CM_ "IMPORT _honda_common.dbc";
CM_ "IMPORT _bosch_2018.dbc";
CM_ "IMPORT _lkas_hud_8byte.dbc";
CM_ "IMPORT _bosch_standstill.dbc";
CM_ "IMPORT _steering_sensors_a.dbc";
CM_ "IMPORT _gearbox_common.dbc";

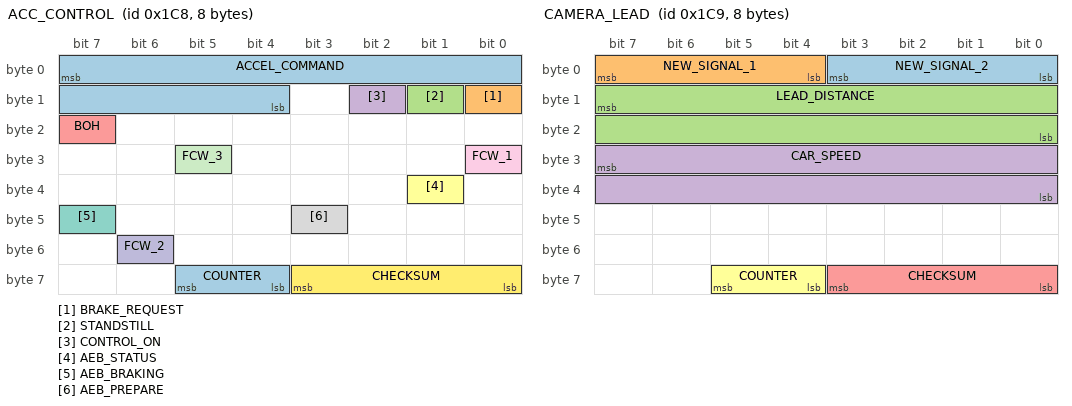
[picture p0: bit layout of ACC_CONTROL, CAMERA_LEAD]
BO_ 456 ACC_CONTROL: 8 XXX
 SG_ ACCEL_COMMAND : 7|12@0- (0.01,0) [0|0] "m/s^2" XXX
 SG_ BRAKE_REQUEST : 8|1@0+ (1,0) [0|1] "" XXX
 SG_ STANDSTILL : 9|1@0+ (1,0) [0|1] "" XXX
 SG_ CONTROL_ON : 10|1@0+ (1,0) [0|1] "" XXX
 SG_ BOH : 23|1@0+ (1,0) [0|1] "" XXX
 SG_ AEB_STATUS : 33|1@1+ (1,0) [0|7] "" XXX
 SG_ AEB_BRAKING : 47|1@0+ (1,0) [0|1] "" XXX
 SG_ AEB_PREPARE : 43|1@0+ (1,0) [0|1] "" XXX
 SG_ FCW_1 : 24|1@1+ (1,0) [0|3] "" XXX
 SG_ FCW_2 : 54|1@0+ (1,0) [0|3] "" XXX
 SG_ FCW_3 : 29|1@0+ (1,0) [0|1] "" XXX
 SG_ CHECKSUM : 59|4@0+ (1,0) [0|15] "" XXX
 SG_ COUNTER : 61|2@0+ (1,0) [0|3] "" XXX

BO_ 457 CAMERA_LEAD: 8 CAM
 SG_ NEW_SIGNAL_2 : 0|4@1+ (1,0) [0|15] "" XXX
 SG_ NEW_SIGNAL_1 : 4|4@1+ (1,0) [0|15] "" XXX
 SG_ LEAD_DISTANCE : 15|16@0+ (1,0) [0|65535] "cm" XXX
 SG_ CAR_SPEED : 31|16@0+ (0.03124,0) [0|65535] "kph" XXX
 SG_ CHECKSUM : 59|4@0+ (1,0) [0|15] "" XXX
 SG_ COUNTER : 61|2@0+ (1,0) [0|3] "" XXX

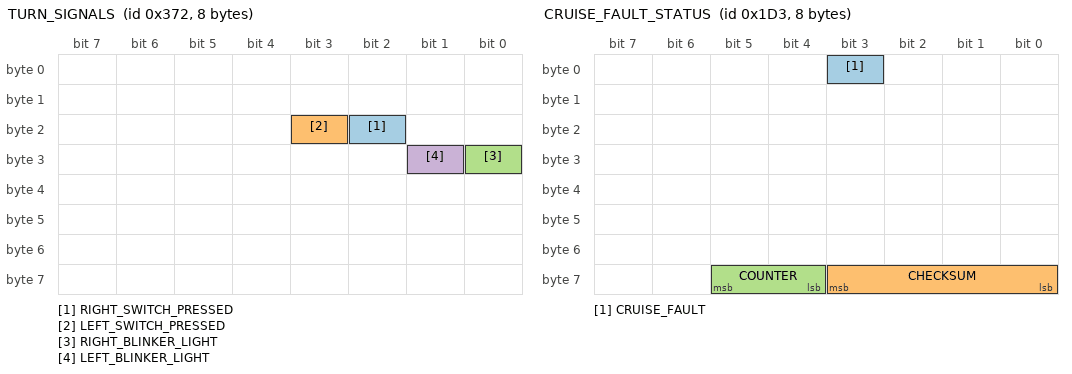
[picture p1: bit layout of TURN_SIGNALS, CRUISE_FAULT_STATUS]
BO_ 882 TURN_SIGNALS: 8 XXX
 SG_ RIGHT_SWITCH_PRESSED : 18|1@0+ (1,0) [0|1] "" XXX
 SG_ LEFT_SWITCH_PRESSED : 19|1@0+ (1,0) [0|1] "" XXX
 SG_ RIGHT_BLINKER_LIGHT : 24|1@0+ (1,0) [0|1] "" XXX
 SG_ LEFT_BLINKER_LIGHT : 25|1@0+ (1,0) [0|1] "" XXX

BO_ 114120023 HUD_OBJECTS: 8 CAM
 SG_ TRACK_INDEX M : 7|6@0+ (1,0) [0|63] "" XXX
 SG_ OBJECT_ID m1 : 15|5@0+ (1,0) [0|31] "" XXX
 SG_ IS_LEAD_CAR m1 : 17|1@0+ (1,0) [0|1] "" XXX
 SG_ CAR_TYPE m1 : 23|4@0- (1,0) [-8|7] "" XXX
 SG_ ROTATION m1 : 31|8@0- (1,0) [-128|127] "" XXX
 SG_ LONG_DIST m1 : 39|10@0+ (0.209,-16.9) [-16.9|196.9] "m" XXX
 SG_ LAT_DIST m1 : 43|12@0- (0.1,0) [-204.8|204.7] "m" XXX
 SG_ CHECKSUM : 59|4@0+ (1,0) [0|15] "" XXX
 SG_ COUNTER : 61|2@0+ (1,0) [0|3] "" XXX

BO_ 114120020 LANE_PATH: 8 CAM
 SG_ MUX M : 7|6@0+ (1,0) [0|63] "" XXX
 SG_ PATH_OFFSET_1 m1 : 15|12@0- (1,0) [-2048|2047] "" XXX
 SG_ PATH_OFFSET_2 m1 : 19|12@0- (1,0) [-2048|2047] "" XXX
 SG_ PATH_OFFSET_3 m1 : 39|12@0- (1,0) [-2048|2047] "" XXX
 SG_ PATH_OFFSET_4 m1 : 43|12@0- (1,0) [-2048|2047] "" XXX
 SG_ CHECKSUM : 59|4@0+ (1,0) [0|15] "" XXX
 SG_ COUNTER : 61|2@0+ (1,0) [0|3] "" XXX

BO_ 467 CRUISE_FAULT_STATUS: 8 XXX
 SG_ CRUISE_FAULT : 3|1@0+ (1,0) [0|1] "" XXX
 SG_ CHECKSUM : 59|4@0+ (1,0) [0|15] "" XXX
 SG_ COUNTER : 61|2@0+ (1,0) [0|3] "" XXX

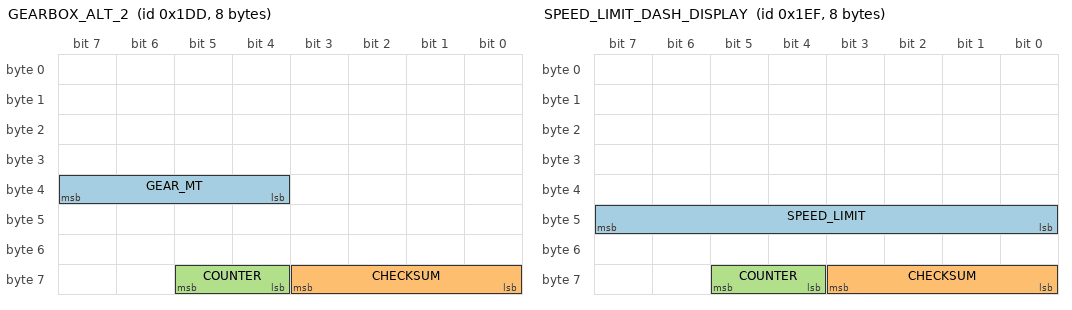
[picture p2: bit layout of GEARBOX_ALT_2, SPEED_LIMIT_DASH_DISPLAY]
BO_ 477 GEARBOX_ALT_2: 8 XXX
 SG_ GEAR_MT : 39|4@0+ (1,0) [0|15] "" XXX
 SG_ CHECKSUM : 59|4@0+ (1,0) [0|15] "" XXX
 SG_ COUNTER : 61|2@0+ (1,0) [0|3] "" XXX

BO_ 495 SPEED_LIMIT_DASH_DISPLAY: 8 ADAS
 SG_ SPEED_LIMIT : 47|8@0+ (1,0) [0|255] "mph" XXX
 SG_ CHECKSUM : 59|4@0+ (1,0) [0|15] "" XXX
 SG_ COUNTER : 61|2@0+ (1,0) [0|3] "" XXX

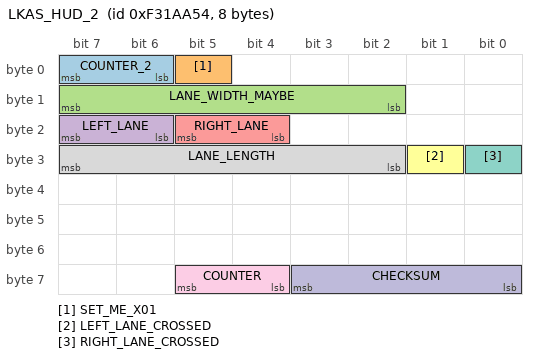
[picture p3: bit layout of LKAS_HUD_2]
BO_ 254913108 LKAS_HUD_2: 8 ADAS
 SG_ COUNTER_2 : 7|2@0+ (1,0) [0|3] "" XXX
 SG_ SET_ME_X01 : 5|1@0+ (1,0) [0|1] "" XXX
 SG_ LANE_WIDTH_MAYBE : 15|6@0+ (1,0) [0|63] "" XXX
 SG_ LEFT_LANE : 23|2@0+ (1,0) [0|3] "" XXX
 SG_ RIGHT_LANE : 21|2@0+ (1,0) [0|3] "" XXX
 SG_ LEFT_LANE_CROSSED : 25|1@0+ (1,0) [0|1] "" XXX
 SG_ RIGHT_LANE_CROSSED : 24|1@0+ (1,0) [0|1] "" XXX
 SG_ LANE_LENGTH : 31|6@0+ (1,0) [0|63] "" XXX
 SG_ COUNTER : 61|2@0+ (1,0) [0|3] "" XXX
 SG_ CHECKSUM : 59|4@0+ (1,0) [0|15] "" XXX

CM_ SG_ 456 IDLESTOP_ALLOW "allows car to turn off engine at a standstill";
CM_ SG_ 456 STANDSTILL "set to 1 when camera requests -4.0 m/s^2";
CM_ SG_ 457 CAR_SPEED "Ego speed, not lead speed";
CM_ SG_ 495 SPEED_LIMIT "Defaults to 0xFF if no speed limit found";
CM_ SG_ 114120023 TRACK_INDEX "1-10, 17-26, 33-42, 49-58 map to the same 10 objects for 5Hz frequency each";
CM_ SG_ 114120023 IS_LEAD_CAR "1 when this track is the lead car; the lead, when present, is always track index 1";
CM_ SG_ 114120023 LAT_DIST "positive = left of ego, 204.7 (max value) when inactive";
CM_ SG_ 114120023 ROTATION "0 straight, negative left, positive right. Range of -3 to 3 seen so far. -128 when inactive.";

VAL_ 477 GEAR_MT 14 "reverse" 6 "6th" 5 "5th" 4 "4th" 3 "3rd" 2 "2nd" 1 "1st" 0 "Clutch";
VAL_ 114120023 CAR_TYPE 7 "CAR" 6 "MOTORCYCLE" -7 "TRUCK" -1 "INACTIVE" 0 "UNKNOWN";
